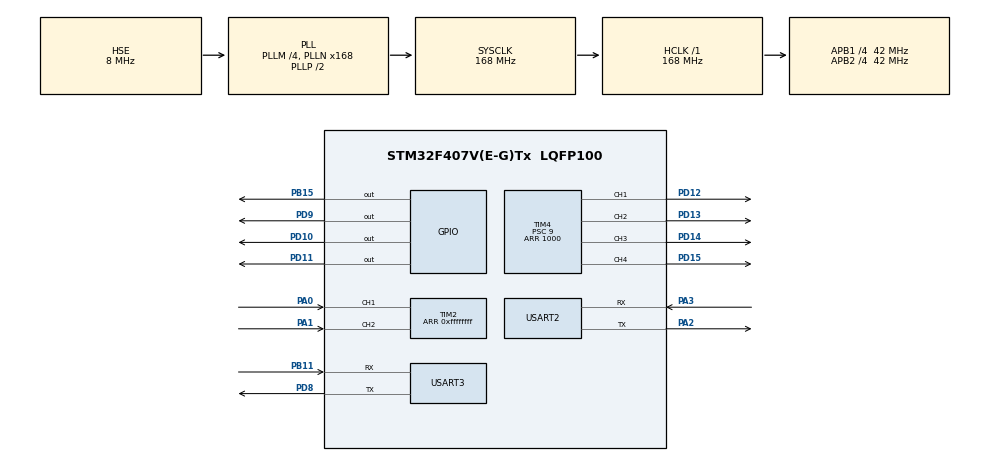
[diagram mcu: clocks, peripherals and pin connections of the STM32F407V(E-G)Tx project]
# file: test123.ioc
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Dma.Request0=USART2_RX
Dma.Request1=USART3_RX
Dma.USART2_RX.0.Direction=DMA_PERIPH_TO_MEMORY
Dma.USART2_RX.0.FIFOMode=DMA_FIFOMODE_DISABLE
Dma.USART2_RX.0.Instance=DMA1_Stream5
Dma.USART2_RX.0.MemDataAlignment=DMA_MDATAALIGN_BYTE
Dma.USART2_RX.0.MemInc=DMA_MINC_ENABLE
Dma.USART2_RX.0.Mode=DMA_CIRCULAR
Dma.USART2_RX.0.PeriphDataAlignment=DMA_PDATAALIGN_BYTE
Dma.USART2_RX.0.PeriphInc=DMA_PINC_DISABLE
Dma.USART2_RX.0.Priority=DMA_PRIORITY_LOW
Dma.USART3_RX.1.Direction=DMA_PERIPH_TO_MEMORY
Dma.USART3_RX.1.FIFOMode=DMA_FIFOMODE_DISABLE
Dma.USART3_RX.1.Instance=DMA1_Stream1
Dma.USART3_RX.1.MemDataAlignment=DMA_MDATAALIGN_BYTE
Dma.USART3_RX.1.MemInc=DMA_MINC_ENABLE
Dma.USART3_RX.1.Mode=DMA_CIRCULAR
Dma.USART3_RX.1.PeriphDataAlignment=DMA_PDATAALIGN_BYTE
Dma.USART3_RX.1.PeriphInc=DMA_PINC_DISABLE
Dma.USART3_RX.1.Priority=DMA_PRIORITY_LOW
Mcu.Family=STM32F4
Mcu.Name=STM32F407V(E-G)Tx
Mcu.Package=LQFP100
NVIC.DMA1_Stream1_IRQn=true\:0\:0\:false\:false\:true\:true
NVIC.DMA1_Stream5_IRQn=true\:0\:0\:false\:false\:true\:true
NVIC.PriorityGroup=NVIC_PRIORITYGROUP_4
NVIC.TIM6_DAC_IRQn=true\:0\:0\:false\:false\:true\:true
NVIC.USART2_IRQn=true\:0\:0\:false\:false\:true\:true
NVIC.USART3_IRQn=true\:0\:0\:false\:false\:true\:true
PA0-WKUP.GPIO_ModeDefaultPP=GPIO_MODE_AF_PP
PA0-WKUP.GPIO_PuPd=GPIO_PULLUP
PA0-WKUP.GPIO_Speed=GPIO_SPEED_FREQ_HIGH
PA0-WKUP.Signal=S_TIM2_CH1_ETR
PA1.GPIO_ModeDefaultPP=GPIO_MODE_AF_PP
PA1.GPIO_PuPd=GPIO_PULLUP
PA1.GPIO_Speed=GPIO_SPEED_FREQ_HIGH
PA1.Signal=S_TIM2_CH2
PA13.Mode=Serial_Wire
PA13.Signal=SYS_JTMS-SWDIO
PA14.Mode=Serial_Wire
PA14.Signal=SYS_JTCK-SWCLK
PA2.Mode=Asynchronous
PA2.Signal=USART2_TX
PA3.Mode=Asynchronous
PA3.Signal=USART2_RX
PB11.Mode=Asynchronous
PB11.Signal=USART3_RX
PB15.GPIO_ModeDefaultOutputPP=GPIO_MODE_OUTPUT_PP
PB15.GPIO_PuPd=GPIO_NOPULL
PB15.GPIO_Speed=GPIO_SPEED_FREQ_HIGH
PB15.PinState=GPIO_PIN_RESET
PB15.Signal=GPIO_Output
PD10.GPIO_ModeDefaultOutputPP=GPIO_MODE_OUTPUT_PP
PD10.GPIO_PuPd=GPIO_NOPULL
PD10.GPIO_Speed=GPIO_SPEED_FREQ_HIGH
PD10.PinState=GPIO_PIN_RESET
PD10.Signal=GPIO_Output
PD11.GPIO_ModeDefaultOutputPP=GPIO_MODE_OUTPUT_PP
PD11.GPIO_PuPd=GPIO_NOPULL
PD11.GPIO_Speed=GPIO_SPEED_FREQ_HIGH
PD11.PinState=GPIO_PIN_RESET
PD11.Signal=GPIO_Output
PD12.GPIO_ModeDefaultPP=GPIO_MODE_AF_PP
PD12.GPIO_PuPd=GPIO_NOPULL
PD12.GPIO_Speed=GPIO_SPEED_FREQ_HIGH
PD12.Signal=S_TIM4_CH1
PD13.GPIO_ModeDefaultPP=GPIO_MODE_AF_PP
PD13.GPIO_PuPd=GPIO_NOPULL
PD13.GPIO_Speed=GPIO_SPEED_FREQ_HIGH
PD13.Signal=S_TIM4_CH2
PD14.GPIO_ModeDefaultPP=GPIO_MODE_AF_PP
PD14.GPIO_PuPd=GPIO_NOPULL
PD14.GPIO_Speed=GPIO_SPEED_FREQ_HIGH
PD14.Signal=S_TIM4_CH3
PD15.GPIO_ModeDefaultPP=GPIO_MODE_AF_PP
PD15.GPIO_PuPd=GPIO_NOPULL
PD15.GPIO_Speed=GPIO_SPEED_FREQ_HIGH
PD15.Signal=S_TIM4_CH4
PD8.Mode=Asynchronous
PD8.Signal=USART3_TX
PD9.GPIO_ModeDefaultOutputPP=GPIO_MODE_OUTPUT_PP
PD9.GPIO_PuPd=GPIO_NOPULL
PD9.GPIO_Speed=GPIO_SPEED_FREQ_HIGH
PD9.PinState=GPIO_PIN_RESET
PD9.Signal=GPIO_Output
PH0-OSC_IN.Mode=HSE-External-Oscillator
PH0-OSC_IN.Signal=RCC_OSC_IN
PH1-OSC_OUT.Mode=HSE-External-Oscillator
PH1-OSC_OUT.Signal=RCC_OSC_OUT
ProjectManager.HeapSize=0x200
ProjectManager.StackSize=0x400
ProjectManager.TargetToolchain=EWARM V7
RCC.48MHZClocksFreq_Value=84000000
RCC.AHBFreq_Value=168000000
RCC.APB1CLKDivider=RCC_HCLK_DIV4
RCC.APB1Freq_Value=42000000
RCC.APB1TimFreq_Value=84000000
RCC.APB2CLKDivider=RCC_HCLK_DIV4
RCC.APB2Freq_Value=42000000
RCC.APB2TimFreq_Value=84000000
RCC.CortexFreq_Value=168000000
RCC.HCLKFreq_Value=168000000
RCC.HSE_VALUE=8000000
RCC.HSI_VALUE=16000000
RCC.LSE_VALUE=8000
RCC.PLLM=4
RCC.PLLN=168
RCC.PLLSourceVirtual=RCC_PLLSOURCE_HSE
RCC.SYSCLKFreq_VALUE=168000000
RCC.SYSCLKSource=RCC_SYSCLKSOURCE_PLLCLK
RCC.VCOOutputFreq_Value=336000000
SH.S_TIM2_CH1_ETR.0=TIM2_CH1,Encoder_Interface
SH.S_TIM2_CH2.0=TIM2_CH2,Encoder_Interface
SH.S_TIM4_CH1.0=TIM4_CH1,PWM Generation1 CH1
SH.S_TIM4_CH2.0=TIM4_CH2,PWM Generation2 CH2
SH.S_TIM4_CH3.0=TIM4_CH3,PWM Generation3 CH3
SH.S_TIM4_CH4.0=TIM4_CH4,PWM Generation4 CH4
TIM2.EncoderMode=TIM_ENCODERMODE_TI12
TIM2.IC1Filter=5
TIM2.IC2Filter=5
TIM2.Period=0xffffffff
TIM4.Channel-PWM\ Generation1\ CH1=TIM_CHANNEL_1
TIM4.Channel-PWM\ Generation2\ CH2=TIM_CHANNEL_2
TIM4.Channel-PWM\ Generation3\ CH3=TIM_CHANNEL_3
TIM4.Channel-PWM\ Generation4\ CH4=TIM_CHANNEL_4
TIM4.Period=1000
TIM4.Prescaler=9
TIM6.Period=999
TIM6.Prescaler=84
USART2.VirtualMode=VM_ASYNC
USART3.VirtualMode=VM_ASYNC
VP_TIM4_VS_ClockSourceINT.Mode=Internal
VP_TIM6_VS_ClockSourceINT.Mode=Enable_Timer
board=test123

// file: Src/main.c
/**
  ******************************************************************************
  * File Name          : main.c
  * Description        : Main program body
  ******************************************************************************
  ** This notice applies to any and all portions of this file
  * that are not between comment pairs USER CODE BEGIN and
  * USER CODE END. Other portions of this file, whether
  * inserted by the user or by software development tools
  * are owned by their respective copyright owners.
  *
  * COPYRIGHT(c) 2018 STMicroelectronics
  *
  * Redistribution and use in source and binary forms, with or without modification,
  * are permitted provided that the following conditions are met:
  *   1. Redistributions of source code must retain the above copyright notice,
  *      this list of conditions and the following disclaimer.
  *   2. Redistributions in binary form must reproduce the above copyright notice,
  *      this list of conditions and the following disclaimer in the documentation
  *      and/or other materials provided with the distribution.
  *   3. Neither the name of STMicroelectronics nor the names of its contributors
  *      may be used to endorse or promote products derived from this software
  *      without specific prior written permission.
  *
  * THIS SOFTWARE IS PROVIDED BY THE COPYRIGHT HOLDERS AND CONTRIBUTORS "AS IS"
  * AND ANY EXPRESS OR IMPLIED WARRANTIES, INCLUDING, BUT NOT LIMITED TO, THE
  * IMPLIED WARRANTIES OF MERCHANTABILITY AND FITNESS FOR A PARTICULAR PURPOSE ARE
  * DISCLAIMED. IN NO EVENT SHALL THE COPYRIGHT HOLDER OR CONTRIBUTORS BE LIABLE
  * FOR ANY DIRECT, INDIRECT, INCIDENTAL, SPECIAL, EXEMPLARY, OR CONSEQUENTIAL
  * DAMAGES (INCLUDING, BUT NOT LIMITED TO, PROCUREMENT OF SUBSTITUTE GOODS OR
  * SERVICES; LOSS OF USE, DATA, OR PROFITS; OR BUSINESS INTERRUPTION) HOWEVER
  * CAUSED AND ON ANY THEORY OF LIABILITY, WHETHER IN CONTRACT, STRICT LIABILITY,
  * OR TORT (INCLUDING NEGLIGENCE OR OTHERWISE) ARISING IN ANY WAY OUT OF THE USE
  * OF THIS SOFTWARE, EVEN IF ADVISED OF THE POSSIBILITY OF SUCH DAMAGE.
  *
  ******************************************************************************
  */
#include "main.h"
#include "stm32f4xx_hal.h"

/* USER CODE BEGIN Includes */
#include "robot_4_wheel.h"
#include "PS2.h"
/* USER CODE END Includes */
extern PS2_stat ps2;
extern robot_4_wheel robot;
TIM_HandleTypeDef htim2;
TIM_HandleTypeDef htim4;
TIM_HandleTypeDef htim6;

UART_HandleTypeDef huart2;
UART_HandleTypeDef huart3;
DMA_HandleTypeDef hdma_usart2_rx;
DMA_HandleTypeDef hdma_usart3_rx;

/* USER CODE BEGIN PV */
/* Private variables ---------------------------------------------------------*/

/* USER CODE END PV */

void SystemClock_Config(void);
static void MX_GPIO_Init(void);
static void MX_DMA_Init(void);
static void MX_TIM2_Init(void);
static void MX_TIM4_Init(void);
static void MX_TIM6_Init(void);
static void MX_USART2_UART_Init(void);
static void MX_USART3_UART_Init(void);

void HAL_TIM_MspPostInit(TIM_HandleTypeDef *htim);

/* USER CODE BEGIN PFP */
/* Private function prototypes -----------------------------------------------*/

/* USER CODE END PFP */

int main(void)
{

  /* MCU Configuration----------------------------------------------------------*/

  /* Reset of all peripherals, Initializes the Flash interface and the Systick. */
  HAL_Init();

  /* Configure the system clock */
  SystemClock_Config();

  /* Initialize all configured peripherals */
  MX_GPIO_Init();
  MX_DMA_Init();
  MX_TIM2_Init();
  MX_TIM4_Init();
  MX_TIM6_Init();
  MX_USART2_UART_Init();
  MX_USART3_UART_Init();

  /* USER CODE BEGIN 2 */
  setUpDe();
  /* USER CODE END 2 */

  /* Infinite loop */
  while (1)
  {

  /* USER CODE BEGIN 3 */
//      A_DUONG;
//      PWM_A(20);

      if(ps2.LX)
    {
      robotRun(100,0,0.5,1);
    }
    if(ps2.R)
    {
      robotRun(100,180,0.5,1);
    }
    if(ps2.U)
    {
      robotRun(100,90,0.5,1);
    }
    if(ps2.X)
    {
      robotRun(100,-90,0.5,1);
    }

  }
  /* USER CODE END 3 */

}

/** System Clock Configuration
*/
void SystemClock_Config(void)
{

  RCC_OscInitTypeDef RCC_OscInitStruct;
  RCC_ClkInitTypeDef RCC_ClkInitStruct;

    /**Configure the main internal regulator output voltage
    */
  __HAL_RCC_PWR_CLK_ENABLE();

  __HAL_PWR_VOLTAGESCALING_CONFIG(PWR_REGULATOR_VOLTAGE_SCALE1);

    /**Initializes the CPU, AHB and APB busses clocks
    */
  RCC_OscInitStruct.OscillatorType = RCC_OSCILLATORTYPE_HSE;
  RCC_OscInitStruct.HSEState = RCC_HSE_ON;
  RCC_OscInitStruct.PLL.PLLState = RCC_PLL_ON;
  RCC_OscInitStruct.PLL.PLLSource = RCC_PLLSOURCE_HSE;
  RCC_OscInitStruct.PLL.PLLM = 4;
  RCC_OscInitStruct.PLL.PLLN = 168;
  RCC_OscInitStruct.PLL.PLLP = RCC_PLLP_DIV2;
  RCC_OscInitStruct.PLL.PLLQ = 4;
  if (HAL_RCC_OscConfig(&RCC_OscInitStruct) != HAL_OK)
  {
    _Error_Handler(__FILE__, __LINE__);
  }

    /**Initializes the CPU, AHB and APB busses clocks
    */
  RCC_ClkInitStruct.ClockType = RCC_CLOCKTYPE_HCLK|RCC_CLOCKTYPE_SYSCLK
                              |RCC_CLOCKTYPE_PCLK1|RCC_CLOCKTYPE_PCLK2;
  RCC_ClkInitStruct.SYSCLKSource = RCC_SYSCLKSOURCE_PLLCLK;
  RCC_ClkInitStruct.AHBCLKDivider = RCC_SYSCLK_DIV1;
  RCC_ClkInitStruct.APB1CLKDivider = RCC_HCLK_DIV4;
  RCC_ClkInitStruct.APB2CLKDivider = RCC_HCLK_DIV4;

  if (HAL_RCC_ClockConfig(&RCC_ClkInitStruct, FLASH_LATENCY_5) != HAL_OK)
  {
    _Error_Handler(__FILE__, __LINE__);
  }

    /**Configure the Systick interrupt time
    */
  HAL_SYSTICK_Config(HAL_RCC_GetHCLKFreq()/1000);

    /**Configure the Systick
    */
  HAL_SYSTICK_CLKSourceConfig(SYSTICK_CLKSOURCE_HCLK);

  /* SysTick_IRQn interrupt configuration */
  HAL_NVIC_SetPriority(SysTick_IRQn, 0, 0);
}

/* TIM2 init function */
static void MX_TIM2_Init(void)
{

  TIM_Encoder_InitTypeDef sConfig;
  TIM_MasterConfigTypeDef sMasterConfig;

  htim2.Instance = TIM2;
  htim2.Init.Prescaler = 0;
  htim2.Init.CounterMode = TIM_COUNTERMODE_UP;
  htim2.Init.Period = 0xffffffff;
  htim2.Init.ClockDivision = TIM_CLOCKDIVISION_DIV1;
  sConfig.EncoderMode = TIM_ENCODERMODE_TI12;
  sConfig.IC1Polarity = TIM_ICPOLARITY_RISING;
  sConfig.IC1Selection = TIM_ICSELECTION_DIRECTTI;
  sConfig.IC1Prescaler = TIM_ICPSC_DIV1;
  sConfig.IC1Filter = 5;
  sConfig.IC2Polarity = TIM_ICPOLARITY_RISING;
  sConfig.IC2Selection = TIM_ICSELECTION_DIRECTTI;
  sConfig.IC2Prescaler = TIM_ICPSC_DIV1;
  sConfig.IC2Filter = 5;
  if (HAL_TIM_Encoder_Init(&htim2, &sConfig) != HAL_OK)
  {
    _Error_Handler(__FILE__, __LINE__);
  }

  sMasterConfig.MasterOutputTrigger = TIM_TRGO_RESET;
  sMasterConfig.MasterSlaveMode = TIM_MASTERSLAVEMODE_DISABLE;
  if (HAL_TIMEx_MasterConfigSynchronization(&htim2, &sMasterConfig) != HAL_OK)
  {
    _Error_Handler(__FILE__, __LINE__);
  }

}

/* TIM4 init function */
static void MX_TIM4_Init(void)
{

  TIM_ClockConfigTypeDef sClockSourceConfig;
  TIM_MasterConfigTypeDef sMasterConfig;
  TIM_OC_InitTypeDef sConfigOC;

  htim4.Instance = TIM4;
  htim4.Init.Prescaler = 9;
  htim4.Init.CounterMode = TIM_COUNTERMODE_UP;
  htim4.Init.Period = 1000;
  htim4.Init.ClockDivision = TIM_CLOCKDIVISION_DIV1;
  if (HAL_TIM_Base_Init(&htim4) != HAL_OK)
  {
    _Error_Handler(__FILE__, __LINE__);
  }

  sClockSourceConfig.ClockSource = TIM_CLOCKSOURCE_INTERNAL;
  if (HAL_TIM_ConfigClockSource(&htim4, &sClockSourceConfig) != HAL_OK)
  {
    _Error_Handler(__FILE__, __LINE__);
  }

  if (HAL_TIM_PWM_Init(&htim4) != HAL_OK)
  {
    _Error_Handler(__FILE__, __LINE__);
  }

  sMasterConfig.MasterOutputTrigger = TIM_TRGO_RESET;
  sMasterConfig.MasterSlaveMode = TIM_MASTERSLAVEMODE_DISABLE;
  if (HAL_TIMEx_MasterConfigSynchronization(&htim4, &sMasterConfig) != HAL_OK)
  {
    _Error_Handler(__FILE__, __LINE__);
  }

  sConfigOC.OCMode = TIM_OCMODE_PWM1;
  sConfigOC.Pulse = 0;
  sConfigOC.OCPolarity = TIM_OCPOLARITY_HIGH;
  sConfigOC.OCFastMode = TIM_OCFAST_DISABLE;
  if (HAL_TIM_PWM_ConfigChannel(&htim4, &sConfigOC, TIM_CHANNEL_1) != HAL_OK)
  {
    _Error_Handler(__FILE__, __LINE__);
  }

  if (HAL_TIM_PWM_ConfigChannel(&htim4, &sConfigOC, TIM_CHANNEL_2) != HAL_OK)
  {
    _Error_Handler(__FILE__, __LINE__);
  }

  if (HAL_TIM_PWM_ConfigChannel(&htim4, &sConfigOC, TIM_CHANNEL_3) != HAL_OK)
  {
    _Error_Handler(__FILE__, __LINE__);
  }

  if (HAL_TIM_PWM_ConfigChannel(&htim4, &sConfigOC, TIM_CHANNEL_4) != HAL_OK)
  {
    _Error_Handler(__FILE__, __LINE__);
  }

  HAL_TIM_MspPostInit(&htim4);

}

/* TIM6 init function */
static void MX_TIM6_Init(void)
{

  TIM_MasterConfigTypeDef sMasterConfig;

  htim6.Instance = TIM6;
  htim6.Init.Prescaler = 84;
  htim6.Init.CounterMode = TIM_COUNTERMODE_UP;
  htim6.Init.Period = 999;
  if (HAL_TIM_Base_Init(&htim6) != HAL_OK)
  {
    _Error_Handler(__FILE__, __LINE__);
  }

  sMasterConfig.MasterOutputTrigger = TIM_TRGO_RESET;
  sMasterConfig.MasterSlaveMode = TIM_MASTERSLAVEMODE_DISABLE;
  if (HAL_TIMEx_MasterConfigSynchronization(&htim6, &sMasterConfig) != HAL_OK)
  {
    _Error_Handler(__FILE__, __LINE__);
  }

}

/* USART2 init function */
static void MX_USART2_UART_Init(void)
{

  huart2.Instance = USART2;
  huart2.Init.BaudRate = 115200;
  huart2.Init.WordLength = UART_WORDLENGTH_8B;
  huart2.Init.StopBits = UART_STOPBITS_1;
  huart2.Init.Parity = UART_PARITY_NONE;
  huart2.Init.Mode = UART_MODE_TX_RX;
  huart2.Init.HwFlowCtl = UART_HWCONTROL_NONE;
  huart2.Init.OverSampling = UART_OVERSAMPLING_16;
  if (HAL_UART_Init(&huart2) != HAL_OK)
  {
    _Error_Handler(__FILE__, __LINE__);
  }

}

/* USART3 init function */
static void MX_USART3_UART_Init(void)
{

  huart3.Instance = USART3;
  huart3.Init.BaudRate = 115200;
  huart3.Init.WordLength = UART_WORDLENGTH_8B;
  huart3.Init.StopBits = UART_STOPBITS_1;
  huart3.Init.Parity = UART_PARITY_NONE;
  huart3.Init.Mode = UART_MODE_TX_RX;
  huart3.Init.HwFlowCtl = UART_HWCONTROL_NONE;
  huart3.Init.OverSampling = UART_OVERSAMPLING_16;
  if (HAL_UART_Init(&huart3) != HAL_OK)
  {
    _Error_Handler(__FILE__, __LINE__);
  }

}

static void MX_DMA_Init(void)
{
  /* DMA controller clock enable */
  __HAL_RCC_DMA1_CLK_ENABLE();

  /* DMA interrupt init */
  /* DMA1_Stream1_IRQn interrupt configuration */
  HAL_NVIC_SetPriority(DMA1_Stream1_IRQn, 0, 0);
  HAL_NVIC_EnableIRQ(DMA1_Stream1_IRQn);
  /* DMA1_Stream5_IRQn interrupt configuration */
  HAL_NVIC_SetPriority(DMA1_Stream5_IRQn, 0, 0);
  HAL_NVIC_EnableIRQ(DMA1_Stream5_IRQn);

}

/** Configure pins as
        * Analog
        * Input
        * Output
        * EVENT_OUT
        * EXTI
*/
static void MX_GPIO_Init(void)
{

  GPIO_InitTypeDef GPIO_InitStruct;

  /* GPIO Ports Clock Enable */
  __HAL_RCC_GPIOH_CLK_ENABLE();
  __HAL_RCC_GPIOA_CLK_ENABLE();
  __HAL_RCC_GPIOB_CLK_ENABLE();
  __HAL_RCC_GPIOD_CLK_ENABLE();

  /*Configure GPIO pin Output Level */
  HAL_GPIO_WritePin(GPIOB, GPIO_PIN_15, GPIO_PIN_RESET);

  /*Configure GPIO pin Output Level */
  HAL_GPIO_WritePin(GPIOD, GPIO_PIN_9|GPIO_PIN_10|GPIO_PIN_11, GPIO_PIN_RESET);

  /*Configure GPIO pin : PB15 */
  GPIO_InitStruct.Pin = GPIO_PIN_15;
  GPIO_InitStruct.Mode = GPIO_MODE_OUTPUT_PP;
  GPIO_InitStruct.Pull = GPIO_NOPULL;
  GPIO_InitStruct.Speed = GPIO_SPEED_FREQ_HIGH;
  HAL_GPIO_Init(GPIOB, &GPIO_InitStruct);

  /*Configure GPIO pins : PD9 PD10 PD11 */
  GPIO_InitStruct.Pin = GPIO_PIN_9|GPIO_PIN_10|GPIO_PIN_11;
  GPIO_InitStruct.Mode = GPIO_MODE_OUTPUT_PP;
  GPIO_InitStruct.Pull = GPIO_NOPULL;
  GPIO_InitStruct.Speed = GPIO_SPEED_FREQ_HIGH;
  HAL_GPIO_Init(GPIOD, &GPIO_InitStruct);

}

void _Error_Handler(char * file, int line)
{
  while(1)
  {
  }
}

/************************ (C) COPYRIGHT STMicroelectronics *****END OF FILE****/
